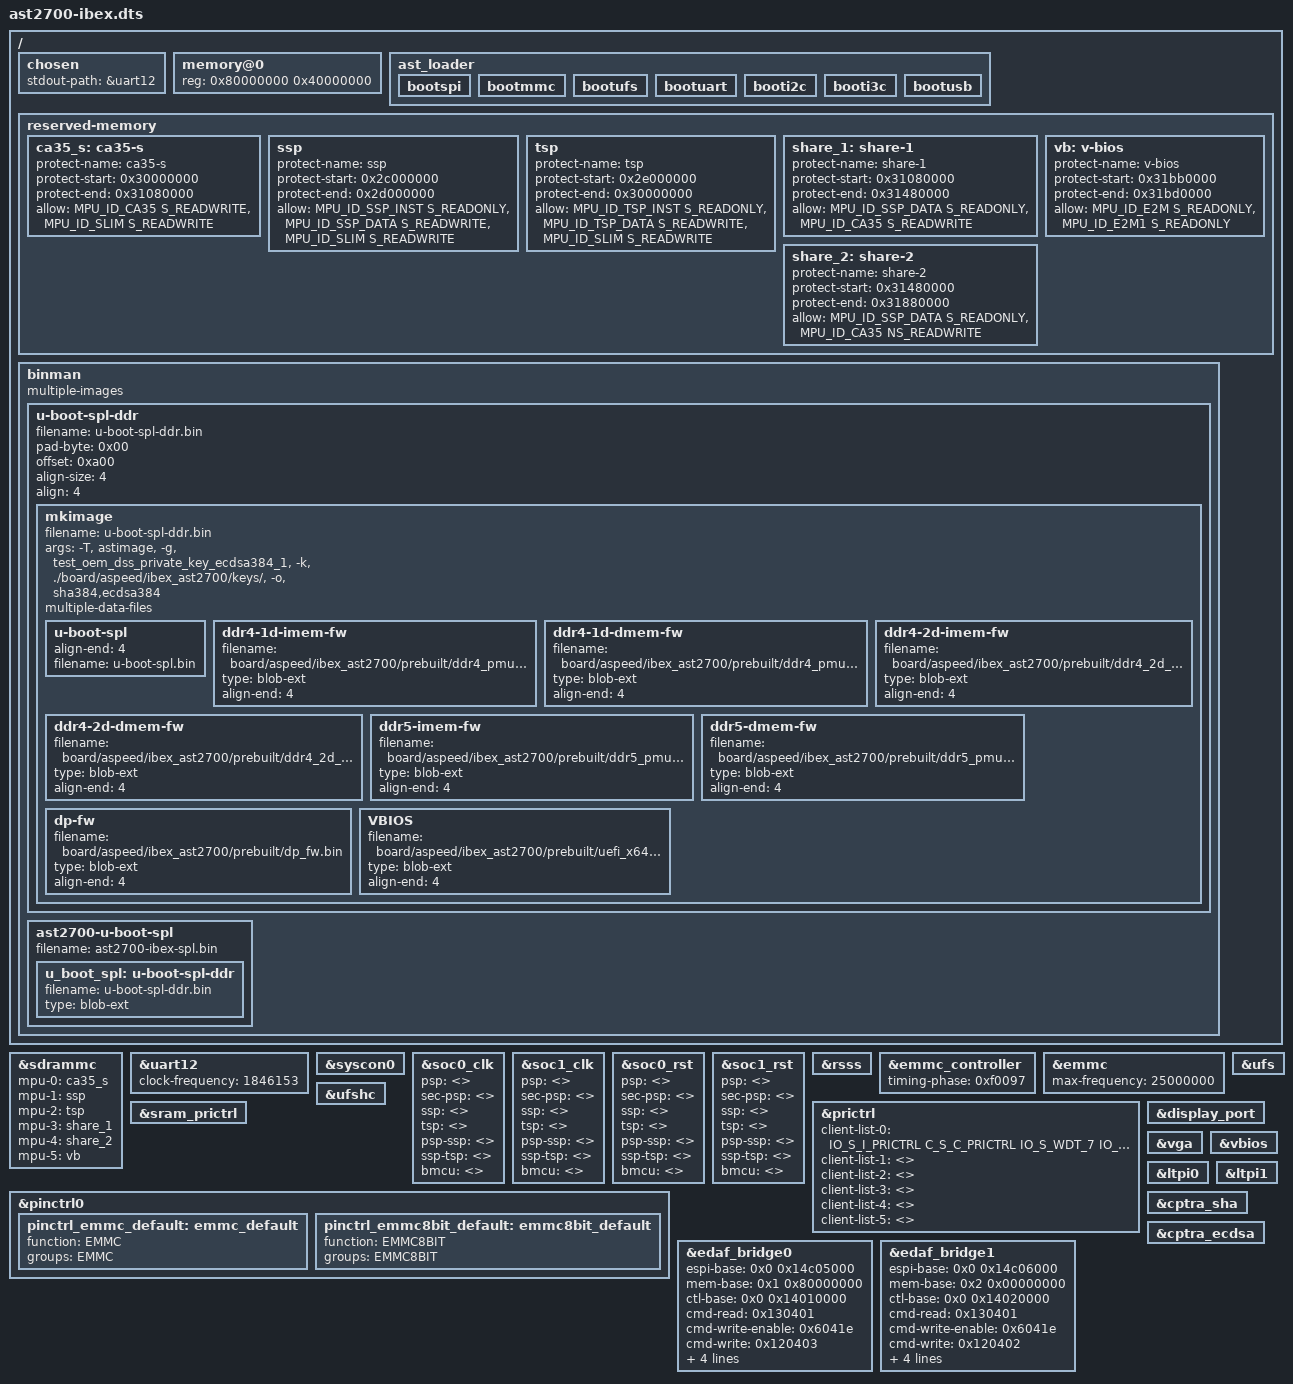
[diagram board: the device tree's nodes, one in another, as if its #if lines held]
// SPDX-License-Identifier: (GPL-2.0 OR MIT)

/dts-v1/;

#include "ast2700.dtsi"

/ {
	chosen {
		stdout-path = &uart12;
	};

	memory@0 {
		device_type = "memory";
		reg = <0x80000000 0x40000000>;
	};

	ast_loader {
		status = "okay";

		bootspi {
			status = "okay";
		};
		bootmmc {
			status = "okay";
		};
		bootufs {
			status = "okay";
		};
		bootuart {
			status = "okay";
		};
		booti2c {
			status = "okay";
		};
		booti3c {
			status = "okay";
		};
		bootusb {
			status = "okay";
		};
	};

	reserved-memory {
		#address-cells = <1>;
		#size-cells = <1>;
		bootph-all;
		ranges;

		#include "ast2700-ibex-reserved-mem.dtsi"

		ca35_s: ca35-s {
			bootph-all;
			protect-name = "ca35-s";
			protect-start = <0x30000000>;
			protect-end = <0x31080000>;
			allow = <MPU_ID_CA35 S_READWRITE>,
				<MPU_ID_SLIM S_READWRITE>;
		};

		ssp: ssp {
			bootph-all;
			protect-name = "ssp";
			protect-start = <0x2c000000>;
			protect-end = <0x2d000000>;
			allow = <MPU_ID_SSP_INST S_READONLY>,
				<MPU_ID_SSP_DATA S_READWRITE>,
				<MPU_ID_SLIM S_READWRITE>;
		};

		tsp: tsp {
			bootph-all;
			protect-name = "tsp";
			protect-start = <0x2e000000>;
			protect-end = <0x30000000>;
			allow = <MPU_ID_TSP_INST S_READONLY>,
				<MPU_ID_TSP_DATA S_READWRITE>,
				<MPU_ID_SLIM S_READWRITE>;
		};

		/* ipc: ssp <=> optee (ca35_s) */
		share_1: share-1 {
			bootph-all;
			protect-name = "share-1";
			protect-start = <0x31080000>;
			protect-end = <0x31480000>;
			allow = <MPU_ID_SSP_DATA S_READONLY>,
				<MPU_ID_CA35 S_READWRITE>;
		};

		/* ipc: ssp <=> linux (ca35_ns) */
		share_2: share-2 {
			bootph-all;
			protect-name = "share-2";
			protect-start = <0x31480000>;
			protect-end = <0x31880000>;
			allow = <MPU_ID_SSP_DATA S_READONLY>,
				<MPU_ID_CA35 NS_READWRITE>;
		};

		vb: v-bios {
			bootph-all;
			protect-name = "v-bios";
			protect-start = <0x31bb0000>;
			protect-end = <0x31bd0000>;
			allow = <MPU_ID_E2M S_READONLY>,
				<MPU_ID_E2M1 S_READONLY>;
		};
	};

	binman: binman {
		multiple-images;
	};
};

&sdrammc {
	status = "okay";
#if 0
	/*
	 * Example of dram ECC enable
	 * The max ECC size = ((Capacity - VGA size) * 8) / 9;
	 * ecc-size for customization, if not set, it will be dynamic detected.
	 */
	ecc-enable;
	ecc-size = <0x38000000>;
	aes-enable;
	aes-size = <0x38000000>;
#endif

#if 1
	/*
	 * Example of memory protection unit
	 */
	mpu-0 = <&ca35_s>;
	mpu-1 = <&ssp>;
	mpu-2 = <&tsp>;
	mpu-3 = <&share_1>;
	mpu-4 = <&share_2>;
	mpu-5 = <&vb>;
#endif
};

&uart12 {
	status = "okay";
	clock-frequency = <1846153>;
};

&syscon0 {
	status = "okay";
};

&soc0_clk {
	psp = <>;
	sec-psp = <>;
	ssp = <>;
	tsp = <>;
	psp-ssp = <>;
	ssp-tsp = <>;
	bmcu = <>;
};

&soc1_clk {
	psp = <>;
	sec-psp = <>;
	ssp = <>;
	tsp = <>;
	psp-ssp = <>;
	ssp-tsp = <>;
	bmcu = <>;
};

&soc0_rst {
	psp = <>;
	sec-psp = <>;
	ssp = <>;
	tsp = <>;
	psp-ssp = <>;
	ssp-tsp = <>;
	bmcu = <>;
};

&soc1_rst {
	psp = <>;
	sec-psp = <>;
	ssp = <>;
	tsp = <>;
	psp-ssp = <>;
	ssp-tsp = <>;
	bmcu = <>;
};

&rsss {
	status = "okay";
};

&emmc_controller {
	status = "okay";
	timing-phase = <0xf0097>;
};

&emmc {
	status = "okay";
	max-frequency = <25000000>;
};

&sram_prictrl {
	status = "okay";
};

&prictrl {
	status = "okay";
	client-list-0 = <IO_S_I_PRICTRL C_S_C_PRICTRL IO_S_WDT_7 IO_S_I_SRAM>;
	client-list-1 = <>;
	client-list-2 = <>;
	client-list-3 = <>;
	client-list-4 = <>;
	client-list-5 = <>;
};

&ufs {
	status = "okay";
};

&ufshc {
	status = "okay";
};

&pinctrl0 {
	pinctrl_emmc_default: emmc_default {
		function = "EMMC";
		groups = "EMMC";
	};

	pinctrl_emmc8bit_default: emmc8bit_default {
		function = "EMMC8BIT";
		groups = "EMMC8BIT";
	};
};

&edaf_bridge0 {
	status = "okay";
	espi-base = <0x0 0x14c05000>;
#if 0 //DDR mode using edaf0 reserved memory
	edaf-ddr-mode;
	edaf-erase-with-1;
	mem-base = <&edaf0>;
#else //Flash mode using SPI0
	mem-base = <0x1 0x80000000>; //SPI0
	ctl-base = <0x0 0x14010000>;
	cmd-read = <0x130401>;
	cmd-write-enable = <0x6041e>;
	cmd-write = <0x120403>;
	cmd-read-status = <0x50415>;
	cmd-erase-4k = <0x21040e>;
	cmd-erase-32k = <0x5c040e>;
	cmd-erase-64k = <0xdc040e>;
#endif
};

&edaf_bridge1 {
	status = "okay";
	espi-base = <0x0 0x14c06000>;
	mem-base = <0x2 0x00000000>; //SPI1
	ctl-base = <0x0 0x14020000>;
	cmd-read = <0x130401>;
	cmd-write-enable = <0x6041e>;
	cmd-write = <0x120402>;
	cmd-read-status = <0x50415>;
	cmd-erase-4k = <0x21040e>;
	cmd-erase-32k = <0x5c040e>;
	cmd-erase-64k = <0xdc040e>;
};

&display_port {
	status = "okay";
};

&vga {
	status = "okay";
};

&vbios {
	status = "okay";
};

&ltpi0 {
	status = "okay";
};

&ltpi1 {
	status = "okay";
};

&cptra_sha {
	status = "okay";
};

&cptra_ecdsa {
	status = "okay";
};

#if BINMAN_SYMS_OK
&binman {
	bootph-all;

	u-boot-spl-ddr {
		bootph-all;
		filename = "u-boot-spl-ddr.bin";
		pad-byte = <0x00>;
		offset = <0xa00>;
		align-size = <4>;
		align = <4>;

		mkimage {
			bootph-all;
			filename = "u-boot-spl-ddr.bin";
			args = "-T", "astimage",
				"-g", "test_oem_dss_private_key_ecdsa384_1",
				"-k", "./board/aspeed/ibex_ast2700/keys/",
				"-o", "sha384,ecdsa384";
			multiple-data-files;

			u-boot-spl {
				bootph-all;
				align-end = <4>;
				filename = "u-boot-spl.bin";
			};

			ddr4-1d-imem-fw {
				bootph-all;
				filename = "board/aspeed/ibex_ast2700/prebuilt/ddr4_pmu_train_imem.bin";
				type = "blob-ext";
				align-end = <4>;
			};
			ddr4-1d-dmem-fw {
				bootph-all;
				filename = "board/aspeed/ibex_ast2700/prebuilt/ddr4_pmu_train_dmem.bin";
				type = "blob-ext";
				align-end = <4>;
			};
			ddr4-2d-imem-fw {
				bootph-all;
				filename = "board/aspeed/ibex_ast2700/prebuilt/ddr4_2d_pmu_train_imem.bin";
				type = "blob-ext";
				align-end = <4>;
			};
			ddr4-2d-dmem-fw {
				bootph-all;
				filename = "board/aspeed/ibex_ast2700/prebuilt/ddr4_2d_pmu_train_dmem.bin";
				type = "blob-ext";
				align-end = <4>;
			};
			ddr5-imem-fw {
				bootph-all;
				filename = "board/aspeed/ibex_ast2700/prebuilt/ddr5_pmu_train_imem.bin";
				type = "blob-ext";
				align-end = <4>;
			};
			ddr5-dmem-fw {
				bootph-all;
				filename = "board/aspeed/ibex_ast2700/prebuilt/ddr5_pmu_train_dmem.bin";
				type = "blob-ext";
				align-end = <4>;
			};
			dp-fw {
				bootph-all;
				filename = "board/aspeed/ibex_ast2700/prebuilt/dp_fw.bin";
				type = "blob-ext";
				align-end = <4>;
			};
			VBIOS {
				bootph-all;
				filename = "board/aspeed/ibex_ast2700/prebuilt/uefi_x64_2700.bin";
				type = "blob-ext";
				align-end = <4>;
			};
		};
	};

	ast2700-u-boot-spl {
		bootph-all;
		filename = "ast2700-ibex-spl.bin";

		u_boot_spl: u-boot-spl-ddr {
			bootph-all;
			filename = "u-boot-spl-ddr.bin";
			type = "blob-ext";
		};
	};
};
#endif
